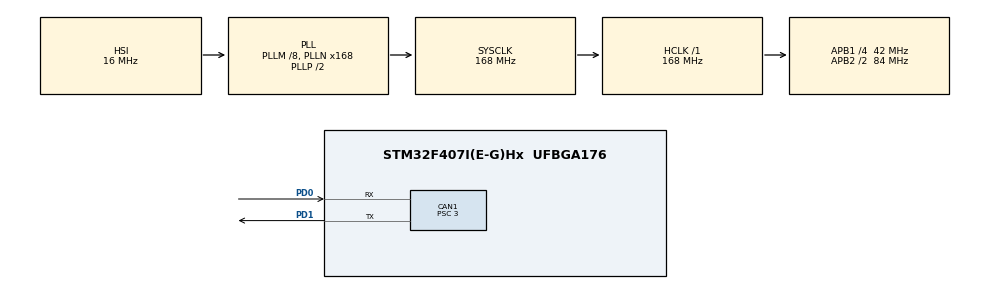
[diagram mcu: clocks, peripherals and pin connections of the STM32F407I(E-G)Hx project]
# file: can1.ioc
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CAN1.ABOM=ENABLE
CAN1.BS1=CAN_BS1_10TQ
CAN1.BS2=CAN_BS2_3TQ
CAN1.CalculateBaudRate=1000000
CAN1.CalculateTimeBit=1000
CAN1.CalculateTimeQuantum=71.42857142857143
CAN1.Prescaler=3
CAN1.TXFP=ENABLE
Mcu.Family=STM32F4
Mcu.Name=STM32F407I(E-G)Hx
Mcu.Package=UFBGA176
NVIC.CAN1_RX0_IRQn=true\:0\:0\:false\:false\:true\:true\:true\:true
NVIC.CAN1_RX1_IRQn=true\:0\:0\:false\:false\:true\:true\:true\:true
NVIC.PriorityGroup=NVIC_PRIORITYGROUP_4
PA13.Mode=Serial_Wire
PA13.Signal=SYS_JTMS-SWDIO
PA14.Mode=Serial_Wire
PA14.Signal=SYS_JTCK-SWCLK
PD0.Mode=CAN_Activate
PD0.Signal=CAN1_RX
PD1.Mode=CAN_Activate
PD1.Signal=CAN1_TX
PH0-OSC_IN.Mode=HSE-External-Oscillator
PH0-OSC_IN.Signal=RCC_OSC_IN
PH1-OSC_OUT.Mode=HSE-External-Oscillator
PH1-OSC_OUT.Signal=RCC_OSC_OUT
ProjectManager.HeapSize=0x200
ProjectManager.StackSize=0x400
ProjectManager.TargetToolchain=Makefile
RCC.48MHZClocksFreq_Value=84000000
RCC.AHBFreq_Value=168000000
RCC.APB1CLKDivider=RCC_HCLK_DIV4
RCC.APB1Freq_Value=42000000
RCC.APB1TimFreq_Value=84000000
RCC.APB2CLKDivider=RCC_HCLK_DIV2
RCC.APB2Freq_Value=84000000
RCC.APB2TimFreq_Value=168000000
RCC.CortexFreq_Value=168000000
RCC.HCLKFreq_Value=168000000
RCC.HSE_VALUE=12000000
RCC.HSI_VALUE=16000000
RCC.PLLM=8
RCC.PLLN=168
RCC.SYSCLKFreq_VALUE=168000000
RCC.SYSCLKSource=RCC_SYSCLKSOURCE_PLLCLK
RCC.VCOOutputFreq_Value=336000000
board=custom

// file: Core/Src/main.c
/* USER CODE BEGIN Header */
/**
  ******************************************************************************
  * @file           : main.c
  * @brief          : Main program body
  ******************************************************************************
  * @attention
  *
  * Copyright (c) 2026 STMicroelectronics.
  * All rights reserved.
  *
  * This software is licensed under terms that can be found in the LICENSE file
  * in the root directory of this software component.
  * If no LICENSE file comes with this software, it is provided AS-IS.
  *
  ******************************************************************************
  */
/* USER CODE END Header */
#include "main.h"
#include "can.h"
#include "gpio.h"

/* USER CODE BEGIN Includes */
#include <math.h>
/* USER CODE END Includes */

/* USER CODE BEGIN PV */
CAN_TxHeaderTypeDef tx_header;
CAN_RxHeaderTypeDef rx_header;
CAN_FilterTypeDef filter;
uint32_t send_mail_box;
typedef struct{
  int16_t angle;
  int16_t speed;
  int16_t current;
  int16_t current1;
  uint8_t temperature;
}Motor1;
volatile Motor1 Motor;
uint8_t tx_data [8];
int16_t current_cmd;
float phase=0.0f;

/* USER CODE END PV */

void SystemClock_Config(void);

int main(void)
{

  /* MCU Configuration--------------------------------------------------------*/

  /* Reset of all peripherals, Initializes the Flash interface and the Systick. */
  HAL_Init();

  /* Configure the system clock */
  SystemClock_Config();

  /* Initialize all configured peripherals */
  MX_GPIO_Init();
  MX_CAN1_Init();
  /* USER CODE BEGIN 2 */
  filter.FilterBank = 0;
  filter.SlaveStartFilterBank = 14;
  filter.FilterMode = CAN_FILTERMODE_IDLIST;
  filter.FilterScale = CAN_FILTERSCALE_16BIT;
  filter.FilterFIFOAssignment = CAN_RX_FIFO1;
  filter.FilterActivation = ENABLE;

  filter.FilterIdHigh     = 0x201 << 5;
  filter.FilterIdLow      = 0x201 << 5;
  filter.FilterMaskIdHigh = 0x201 << 5;
  filter.FilterMaskIdLow  = 0x201 << 5;
  HAL_CAN_ConfigFilter(&hcan1, &filter);
  HAL_CAN_Start(&hcan1);
  HAL_CAN_ActivateNotification(&hcan1, CAN_IT_RX_FIFO1_MSG_PENDING);

  tx_header.StdId = 0x200;
  tx_header.IDE = CAN_ID_STD;
  tx_header.RTR = CAN_RTR_DATA;
  tx_header.DLC = 8;

  /* USER CODE END 2 */

  /* Infinite loop */
  while (1)
  {

    /* USER CODE BEGIN 3 */
  current_cmd = (int16_t)(2000.0f * sinf(phase));
  phase += 0.02f * 3.14159265f;

  uint16_t raw_cmd = (uint16_t)current_cmd;
  tx_data[0] = (uint8_t)(raw_cmd >> 8);
  tx_data[1] = (uint8_t)(raw_cmd & 0xFF);

  for (uint8_t i = 2; i < 8; i++) {
    tx_data[i] = 0;
}
if (HAL_CAN_GetTxMailboxesFreeLevel(&hcan1) > 0) {
    HAL_CAN_AddTxMessage(&hcan1, &tx_header, tx_data, &send_mail_box);
}

HAL_Delay(10);

}
  /* USER CODE END 3 */
}

void SystemClock_Config(void)
{
  RCC_OscInitTypeDef RCC_OscInitStruct = {0};
  RCC_ClkInitTypeDef RCC_ClkInitStruct = {0};

  /** Configure the main internal regulator output voltage
  */
  __HAL_RCC_PWR_CLK_ENABLE();
  __HAL_PWR_VOLTAGESCALING_CONFIG(PWR_REGULATOR_VOLTAGE_SCALE1);

  /** Initializes the RCC Oscillators according to the specified parameters
  * in the RCC_OscInitTypeDef structure.
  */
  RCC_OscInitStruct.OscillatorType = RCC_OSCILLATORTYPE_HSI;
  RCC_OscInitStruct.HSIState = RCC_HSI_ON;
  RCC_OscInitStruct.HSICalibrationValue = RCC_HSICALIBRATION_DEFAULT;
  RCC_OscInitStruct.PLL.PLLState = RCC_PLL_ON;
  RCC_OscInitStruct.PLL.PLLSource = RCC_PLLSOURCE_HSI;
  RCC_OscInitStruct.PLL.PLLM = 8;
  RCC_OscInitStruct.PLL.PLLN = 168;
  RCC_OscInitStruct.PLL.PLLP = RCC_PLLP_DIV2;
  RCC_OscInitStruct.PLL.PLLQ = 4;
  if (HAL_RCC_OscConfig(&RCC_OscInitStruct) != HAL_OK)
  {
    Error_Handler();
  }

  /** Initializes the CPU, AHB and APB buses clocks
  */
  RCC_ClkInitStruct.ClockType = RCC_CLOCKTYPE_HCLK|RCC_CLOCKTYPE_SYSCLK
                              |RCC_CLOCKTYPE_PCLK1|RCC_CLOCKTYPE_PCLK2;
  RCC_ClkInitStruct.SYSCLKSource = RCC_SYSCLKSOURCE_PLLCLK;
  RCC_ClkInitStruct.AHBCLKDivider = RCC_SYSCLK_DIV1;
  RCC_ClkInitStruct.APB1CLKDivider = RCC_HCLK_DIV4;
  RCC_ClkInitStruct.APB2CLKDivider = RCC_HCLK_DIV2;

  if (HAL_RCC_ClockConfig(&RCC_ClkInitStruct, FLASH_LATENCY_5) != HAL_OK)
  {
    Error_Handler();
  }
}

/* USER CODE BEGIN 4 */
void HAL_CAN_RxFifo1MsgPendingCallback(CAN_HandleTypeDef*hcan){
  uint8_t rx_data[8];
  if(hcan==&hcan1){
    if (HAL_CAN_GetRxMessage(hcan, CAN_RX_FIFO1, &rx_header, rx_data) == HAL_OK){
    if(rx_header.StdId==0x201){
       Motor.angle = (int16_t)((rx_data[0] << 8) | rx_data[1]);
       Motor.speed = (int16_t)((rx_data[2] << 8) | rx_data[3]);
       Motor.current = (int16_t)((rx_data[4] << 8) | rx_data[5]);
       Motor.temperature = rx_data[6];
       float alpha = 0.2f;
      Motor.current1 = (int16_t)((1.0f - alpha) * Motor.current1 + alpha * Motor.current);
    }}
  }
}

/* USER CODE END 4 */

void Error_Handler(void)
{
  __disable_irq();
  while (1)
  {
  }
}
